VERSION ""

NS_ :

BS_:

BU_: IVI BCM CLU CGW

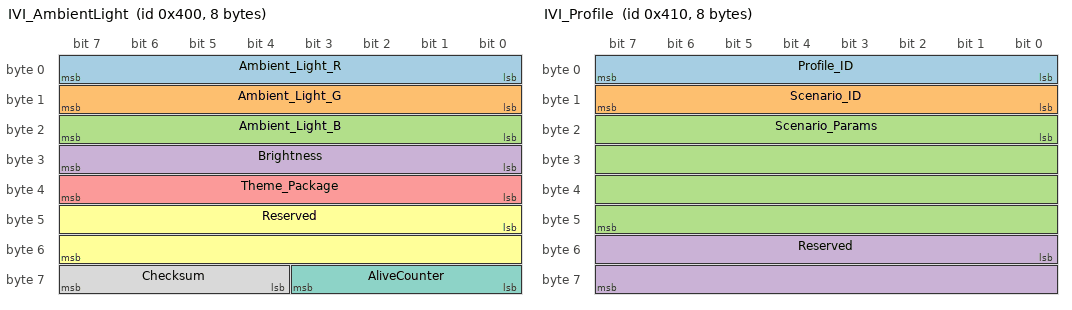
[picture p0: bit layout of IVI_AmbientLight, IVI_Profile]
BO_ 1024 IVI_AmbientLight: 8 IVI
 SG_ Ambient_Light_R : 0|8@1+ (1,0) [0|255] "" BCM
 SG_ Ambient_Light_G : 8|8@1+ (1,0) [0|255] "" BCM
 SG_ Ambient_Light_B : 16|8@1+ (1,0) [0|255] "" BCM
 SG_ Brightness : 24|8@1+ (0.4,0) [0|100] "%" BCM
 SG_ Theme_Package : 32|8@1+ (1,0) [0|10] "" BCM
 SG_ Reserved : 40|16@1+ (1,0) [0|65535] "" BCM
 SG_ AliveCounter : 56|4@1+ (1,0) [0|15] "" CGW
 SG_ Checksum : 60|4@1+ (1,0) [0|15] "" CGW

BO_ 1040 IVI_Profile: 8 IVI
 SG_ Profile_ID : 0|8@1+ (1,0) [0|5] "" BCM
 SG_ Scenario_ID : 8|8@1+ (1,0) [0|20] "" BCM
 SG_ Scenario_Params : 16|32@1+ (1,0) [0|4294967295] "" BCM
 SG_ Reserved : 48|16@1+ (1,0) [0|65535] "" BCM

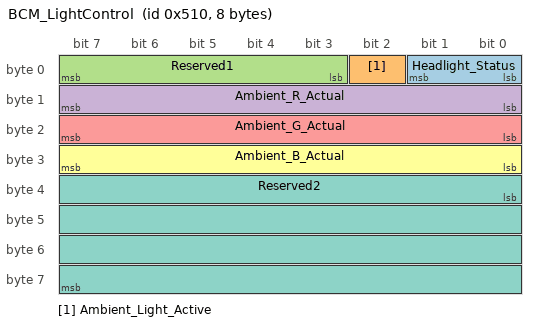
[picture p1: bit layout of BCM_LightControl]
BO_ 1296 BCM_LightControl: 8 BCM
 SG_ Headlight_Status : 0|2@1+ (1,0) [0|3] "" CLU
 SG_ Ambient_Light_Active : 2|1@1+ (1,0) [0|1] "" CLU
 SG_ Reserved1 : 3|5@1+ (1,0) [0|31] "" CLU
 SG_ Ambient_R_Actual : 8|8@1+ (1,0) [0|255] "" CGW
 SG_ Ambient_G_Actual : 16|8@1+ (1,0) [0|255] "" CGW
 SG_ Ambient_B_Actual : 24|8@1+ (1,0) [0|255] "" CGW
 SG_ Reserved2 : 32|32@1+ (1,0) [0|4294967295] "" CGW

CM_ BO_ 1024 "IVI Ambient Lighting Control - Project Specific Feature for RGB ambient lighting with theme packages";
CM_ BO_ 1040 "IVI User Profile Management - Project Specific Feature for user profile and scenario management";
CM_ BO_ 1296 "BCM Light Control with Ambient Feedback - Project Specific Feature for ambient light status feedback";

CM_ SG_ 1024 Ambient_Light_R "Red component of RGB ambient light (0-255)";
CM_ SG_ 1024 Ambient_Light_G "Green component of RGB ambient light (0-255)";
CM_ SG_ 1024 Ambient_Light_B "Blue component of RGB ambient light (0-255)";
CM_ SG_ 1024 Brightness "Overall brightness percentage (0-100%)";
CM_ SG_ 1024 Theme_Package "Predefined theme package selection (0-10)";
CM_ SG_ 1024 AliveCounter "Message alive counter for fault detection (0-15)";
CM_ SG_ 1024 Checksum "Message checksum for data integrity (0-15)";

CM_ SG_ 1040 Profile_ID "User profile identifier (0=DRIVER1, 1=DRIVER2, 2=DRIVER3, 3=GUEST, 4=VALET, 5=CUSTOM)";
CM_ SG_ 1040 Scenario_ID "Scenario identifier (0-20 predefined scenarios)";
CM_ SG_ 1040 Scenario_Params "Scenario-specific parameters (32-bit)";

CM_ SG_ 1296 Headlight_Status "Headlight status (0=OFF, 1=PARKING, 2=LOW_BEAM, 3=HIGH_BEAM)";
CM_ SG_ 1296 Ambient_Light_Active "Ambient light system active status (0=INACTIVE, 1=ACTIVE)";
CM_ SG_ 1296 Ambient_R_Actual "Actual red component output from BCM (0-255)";
CM_ SG_ 1296 Ambient_G_Actual "Actual green component output from BCM (0-255)";
CM_ SG_ 1296 Ambient_B_Actual "Actual blue component output from BCM (0-255)";

BA_DEF_ BO_ "GenMsgCycleTime" INT 0 10000;
BA_DEF_ BO_ "GenMsgSendType" ENUM "Cyclic","Event","IfActive","NoMsgSendType";

BA_DEF_DEF_ "GenMsgCycleTime" 0;
BA_DEF_DEF_ "GenMsgSendType" "Cyclic";

BA_ "GenMsgCycleTime" BO_ 1024 100;
BA_ "GenMsgCycleTime" BO_ 1040 1000;
BA_ "GenMsgSendType" BO_ 1040 "Event";
BA_ "GenMsgCycleTime" BO_ 1296 100;

VAL_ 1024 Theme_Package 0 "SPORT" 1 "COMFORT" 2 "ECO" 3 "CUSTOM1" 4 "CUSTOM2" 5 "CUSTOM3" 6 "NIGHT" 7 "PARTY" 8 "RELAX" 9 "DYNAMIC" 10 "USER_DEFINED";
VAL_ 1040 Profile_ID 0 "DRIVER1" 1 "DRIVER2" 2 "DRIVER3" 3 "GUEST" 4 "VALET" 5 "CUSTOM";
VAL_ 1296 Headlight_Status 0 "OFF" 1 "PARKING" 2 "LOW_BEAM" 3 "HIGH_BEAM";
VAL_ 1296 Ambient_Light_Active 0 "INACTIVE" 1 "ACTIVE";
